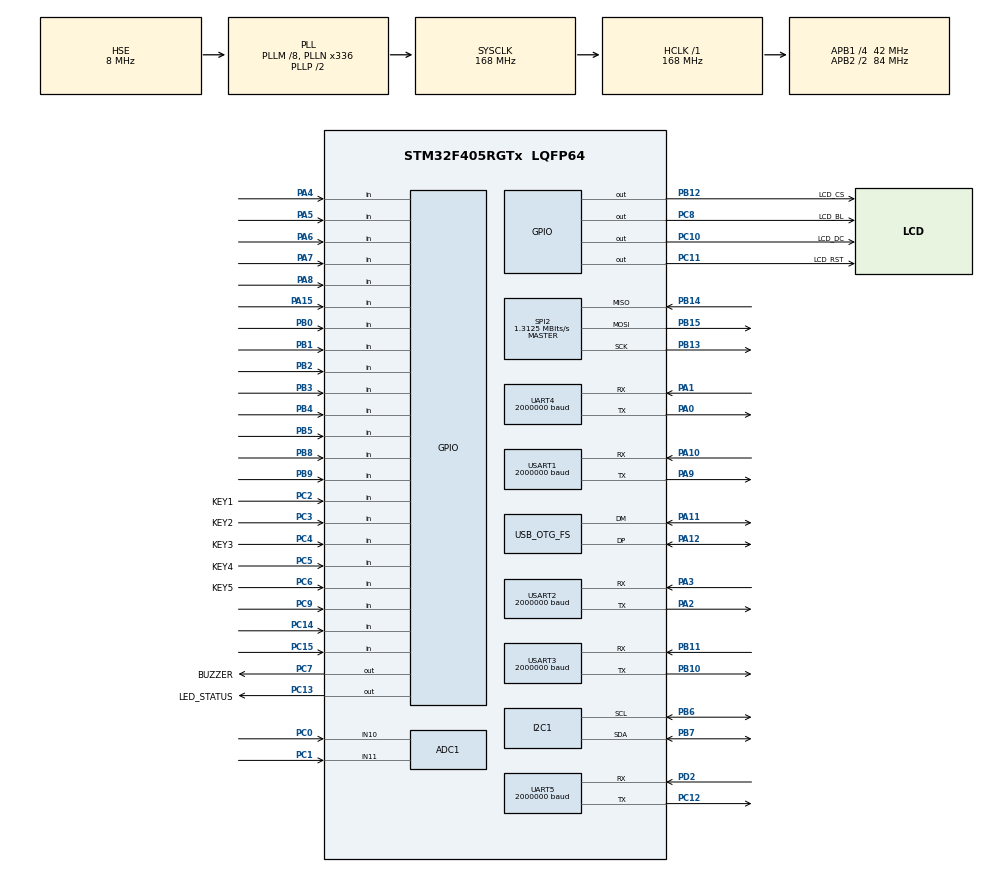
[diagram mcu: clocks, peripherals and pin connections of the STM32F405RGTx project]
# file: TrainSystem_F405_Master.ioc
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ADC1.Channel-3\#ChannelRegularConversion=ADC_CHANNEL_10
ADC1.Channel-6\#ChannelRegularConversion=ADC_CHANNEL_11
ADC1.InjNumberOfConversion=0
ADC1.NbrOfConversion=2
ADC1.NbrOfConversionFlag=1
ADC1.Rank-3\#ChannelRegularConversion=1
ADC1.Rank-6\#ChannelRegularConversion=2
ADC1.SamplingTime-3\#ChannelRegularConversion=ADC_SAMPLETIME_144CYCLES
ADC1.SamplingTime-6\#ChannelRegularConversion=ADC_SAMPLETIME_144CYCLES
ADC1.ScanConvMode=ENABLE
ADC1.master=1
Dma.ADC1.5.Direction=DMA_PERIPH_TO_MEMORY
Dma.ADC1.5.FIFOMode=DMA_FIFOMODE_DISABLE
Dma.ADC1.5.Instance=DMA2_Stream0
Dma.ADC1.5.MemDataAlignment=DMA_MDATAALIGN_HALFWORD
Dma.ADC1.5.MemInc=DMA_MINC_ENABLE
Dma.ADC1.5.Mode=DMA_CIRCULAR
Dma.ADC1.5.PeriphDataAlignment=DMA_PDATAALIGN_HALFWORD
Dma.ADC1.5.PeriphInc=DMA_PINC_DISABLE
Dma.ADC1.5.Priority=DMA_PRIORITY_LOW
Dma.Request0=UART5_RX
Dma.Request1=UART4_RX
Dma.Request2=USART1_RX
Dma.Request3=USART2_RX
Dma.Request4=USART3_RX
Dma.Request5=ADC1
Dma.UART4_RX.1.Direction=DMA_PERIPH_TO_MEMORY
Dma.UART4_RX.1.FIFOMode=DMA_FIFOMODE_DISABLE
Dma.UART4_RX.1.Instance=DMA1_Stream2
Dma.UART4_RX.1.MemDataAlignment=DMA_MDATAALIGN_BYTE
Dma.UART4_RX.1.MemInc=DMA_MINC_ENABLE
Dma.UART4_RX.1.Mode=DMA_CIRCULAR
Dma.UART4_RX.1.PeriphDataAlignment=DMA_PDATAALIGN_BYTE
Dma.UART4_RX.1.PeriphInc=DMA_PINC_DISABLE
Dma.UART4_RX.1.Priority=DMA_PRIORITY_HIGH
Dma.UART5_RX.0.Direction=DMA_PERIPH_TO_MEMORY
Dma.UART5_RX.0.FIFOMode=DMA_FIFOMODE_DISABLE
Dma.UART5_RX.0.Instance=DMA1_Stream0
Dma.UART5_RX.0.MemDataAlignment=DMA_MDATAALIGN_BYTE
Dma.UART5_RX.0.MemInc=DMA_MINC_ENABLE
Dma.UART5_RX.0.Mode=DMA_CIRCULAR
Dma.UART5_RX.0.PeriphDataAlignment=DMA_PDATAALIGN_BYTE
Dma.UART5_RX.0.PeriphInc=DMA_PINC_DISABLE
Dma.UART5_RX.0.Priority=DMA_PRIORITY_HIGH
Dma.USART1_RX.2.Direction=DMA_PERIPH_TO_MEMORY
Dma.USART1_RX.2.FIFOMode=DMA_FIFOMODE_DISABLE
Dma.USART1_RX.2.Instance=DMA2_Stream2
Dma.USART1_RX.2.MemDataAlignment=DMA_MDATAALIGN_BYTE
Dma.USART1_RX.2.MemInc=DMA_MINC_ENABLE
Dma.USART1_RX.2.Mode=DMA_CIRCULAR
Dma.USART1_RX.2.PeriphDataAlignment=DMA_PDATAALIGN_BYTE
Dma.USART1_RX.2.PeriphInc=DMA_PINC_DISABLE
Dma.USART1_RX.2.Priority=DMA_PRIORITY_HIGH
Dma.USART2_RX.3.Direction=DMA_PERIPH_TO_MEMORY
Dma.USART2_RX.3.FIFOMode=DMA_FIFOMODE_DISABLE
Dma.USART2_RX.3.Instance=DMA1_Stream5
Dma.USART2_RX.3.MemDataAlignment=DMA_MDATAALIGN_BYTE
Dma.USART2_RX.3.MemInc=DMA_MINC_ENABLE
Dma.USART2_RX.3.Mode=DMA_CIRCULAR
Dma.USART2_RX.3.PeriphDataAlignment=DMA_PDATAALIGN_BYTE
Dma.USART2_RX.3.PeriphInc=DMA_PINC_DISABLE
Dma.USART2_RX.3.Priority=DMA_PRIORITY_HIGH
Dma.USART3_RX.4.Direction=DMA_PERIPH_TO_MEMORY
Dma.USART3_RX.4.FIFOMode=DMA_FIFOMODE_DISABLE
Dma.USART3_RX.4.Instance=DMA1_Stream1
Dma.USART3_RX.4.MemDataAlignment=DMA_MDATAALIGN_BYTE
Dma.USART3_RX.4.MemInc=DMA_MINC_ENABLE
Dma.USART3_RX.4.Mode=DMA_CIRCULAR
Dma.USART3_RX.4.PeriphDataAlignment=DMA_PDATAALIGN_BYTE
Dma.USART3_RX.4.PeriphInc=DMA_PINC_DISABLE
Dma.USART3_RX.4.Priority=DMA_PRIORITY_HIGH
Mcu.Family=STM32F4
Mcu.Name=STM32F405RGTx
Mcu.Package=LQFP64
NVIC.DMA1_Stream0_IRQn=true\:0\:0\:false\:false\:true\:false\:true\:true
NVIC.DMA1_Stream1_IRQn=true\:0\:0\:false\:false\:true\:false\:true\:true
NVIC.DMA1_Stream2_IRQn=true\:0\:0\:false\:false\:true\:false\:true\:true
NVIC.DMA1_Stream5_IRQn=true\:0\:0\:false\:false\:true\:false\:true\:true
NVIC.DMA2_Stream0_IRQn=true\:0\:0\:false\:false\:true\:false\:true\:true
NVIC.DMA2_Stream2_IRQn=true\:0\:0\:false\:false\:true\:false\:true\:true
NVIC.OTG_FS_IRQn=true\:0\:0\:false\:false\:true\:false\:true\:true
NVIC.PriorityGroup=NVIC_PRIORITYGROUP_4
NVIC.UART4_IRQn=true\:0\:0\:false\:false\:true\:true\:true\:true
NVIC.UART5_IRQn=true\:0\:0\:false\:false\:true\:true\:true\:true
NVIC.USART1_IRQn=true\:0\:0\:false\:false\:true\:true\:true\:true
NVIC.USART2_IRQn=true\:0\:0\:false\:false\:true\:true\:true\:true
NVIC.USART3_IRQn=true\:0\:0\:false\:false\:true\:true\:true\:true
PA0-WKUP.Mode=Asynchronous
PA0-WKUP.Signal=UART4_TX
PA1.Mode=Asynchronous
PA1.Signal=UART4_RX
PA10.Mode=Asynchronous
PA10.Signal=USART1_RX
PA11.Mode=Device_Only
PA11.Signal=USB_OTG_FS_DM
PA12.Mode=Device_Only
PA12.Signal=USB_OTG_FS_DP
PA13.Mode=Serial_Wire
PA13.Signal=SYS_JTMS-SWDIO
PA14.Mode=Serial_Wire
PA14.Signal=SYS_JTCK-SWCLK
PA15.Signal=GPIO_Input
PA2.Mode=Asynchronous
PA2.Signal=USART2_TX
PA3.Mode=Asynchronous
PA3.Signal=USART2_RX
PA4.Signal=GPIO_Input
PA5.Signal=GPIO_Input
PA6.Signal=GPIO_Input
PA7.Signal=GPIO_Input
PA8.Signal=GPIO_Input
PA9.Mode=Asynchronous
PA9.Signal=USART1_TX
PB0.Signal=GPIO_Input
PB1.Signal=GPIO_Input
PB10.Mode=Asynchronous
PB10.Signal=USART3_TX
PB11.Mode=Asynchronous
PB11.Signal=USART3_RX
PB12.GPIO_Label=LCD_CS
PB12.PinState=GPIO_PIN_SET
PB12.Signal=GPIO_Output
PB13.Mode=Full_Duplex_Master
PB13.Signal=SPI2_SCK
PB14.Mode=Full_Duplex_Master
PB14.Signal=SPI2_MISO
PB15.Mode=Full_Duplex_Master
PB15.Signal=SPI2_MOSI
PB2.Signal=GPIO_Input
PB3.Signal=GPIO_Input
PB4.Signal=GPIO_Input
PB5.Signal=GPIO_Input
PB6.Mode=I2C
PB6.Signal=I2C1_SCL
PB7.Mode=I2C
PB7.Signal=I2C1_SDA
PB8.Signal=GPIO_Input
PB9.Signal=GPIO_Input
PC0.Signal=ADCx_IN10
PC1.Signal=ADCx_IN11
PC10.GPIO_Label=LCD_DC
PC10.Signal=GPIO_Output
PC11.GPIO_Label=LCD_RST
PC11.PinState=GPIO_PIN_SET
PC11.Signal=GPIO_Output
PC12.Mode=Asynchronous
PC12.Signal=UART5_TX
PC13-ANTI_TAMP.GPIO_Label=LED_STATUS
PC13-ANTI_TAMP.PinState=GPIO_PIN_SET
PC13-ANTI_TAMP.Signal=GPIO_Output
PC14-OSC32_IN.Signal=GPIO_Input
PC15-OSC32_OUT.Signal=GPIO_Input
PC2.GPIO_Label=KEY1
PC2.Signal=GPIO_Input
PC3.GPIO_Label=KEY2
PC3.Signal=GPIO_Input
PC4.GPIO_Label=KEY3
PC4.Signal=GPIO_Input
PC5.GPIO_Label=KEY4
PC5.Signal=GPIO_Input
PC6.GPIO_Label=KEY5
PC6.Signal=GPIO_Input
PC7.GPIO_Label=BUZZER
PC7.Signal=GPIO_Output
PC8.GPIO_Label=LCD_BL
PC8.Signal=GPIO_Output
PC9.Signal=GPIO_Input
PD2.Mode=Asynchronous
PD2.Signal=UART5_RX
PH0-OSC_IN.Mode=HSE-External-Oscillator
PH0-OSC_IN.Signal=RCC_OSC_IN
PH1-OSC_OUT.Mode=HSE-External-Oscillator
PH1-OSC_OUT.Signal=RCC_OSC_OUT
ProjectManager.HeapSize=0x200
ProjectManager.StackSize=0x400
ProjectManager.TargetToolchain=CMake
RCC.48MHZClocksFreq_Value=48000000
RCC.AHBFreq_Value=168000000
RCC.APB1CLKDivider=RCC_HCLK_DIV4
RCC.APB1Freq_Value=42000000
RCC.APB1TimFreq_Value=84000000
RCC.APB2CLKDivider=RCC_HCLK_DIV2
RCC.APB2Freq_Value=84000000
RCC.APB2TimFreq_Value=168000000
RCC.CortexFreq_Value=168000000
RCC.HCLKFreq_Value=168000000
RCC.HSE_VALUE=8000000
RCC.HSI_VALUE=16000000
RCC.LSE_VALUE=32768
RCC.PLLM=8
RCC.PLLN=336
RCC.PLLQ=7
RCC.SYSCLKFreq_VALUE=168000000
RCC.SYSCLKSource=RCC_SYSCLKSOURCE_PLLCLK
RCC.VCOOutputFreq_Value=336000000
SH.ADCx_IN10.0=ADC1_IN10,IN10
SH.ADCx_IN11.0=ADC1_IN11,IN11
SPI2.BaudRatePrescaler=SPI_BAUDRATEPRESCALER_32
SPI2.CalculateBaudRate=1.3125 MBits/s
SPI2.Direction=SPI_DIRECTION_2LINES
SPI2.Mode=SPI_MODE_MASTER
SPI2.VirtualType=VM_MASTER
UART4.BaudRate=2000000
UART4.VirtualMode=Asynchronous
UART5.BaudRate=2000000
UART5.VirtualMode=Asynchronous
USART1.BaudRate=2000000
USART1.VirtualMode=VM_ASYNC
USART2.BaudRate=2000000
USART2.VirtualMode=VM_ASYNC
USART3.BaudRate=2000000
USART3.VirtualMode=VM_ASYNC
USB_DEVICE.CLASS_NAME_FS=CDC
USB_DEVICE.VirtualMode-CDC_FS=Cdc
USB_DEVICE.VirtualModeFS=Cdc_FS
USB_OTG_FS.VirtualMode=Device_Only
VP_USB_DEVICE_VS_USB_DEVICE_CDC_FS.Mode=CDC_FS
board=custom

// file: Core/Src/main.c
/* USER CODE BEGIN Header */
/**
  ******************************************************************************
  * @file           : main.c
  * @brief          : Main program body
  ******************************************************************************
  * @attention
  *
  * Copyright (c) 2026 STMicroelectronics.
  * All rights reserved.
  *
  * This software is licensed under terms that can be found in the LICENSE file
  * in the root directory of this software component.
  * If no LICENSE file comes with this software, it is provided AS-IS.
  *
  ******************************************************************************
  */
/* USER CODE END Header */
#include "main.h"
#include "adc.h"
#include "dma.h"
#include "i2c.h"
#include "spi.h"
#include "usart.h"
#include "usb_device.h"
#include "gpio.h"

/* USER CODE BEGIN Includes */
#include "app_main.h"

/* USER CODE END Includes */

void SystemClock_Config(void);

int main(void)
{

  /* MCU Configuration--------------------------------------------------------*/

  /* Reset of all peripherals, Initializes the Flash interface and the Systick. */
  HAL_Init();

  /* Configure the system clock */
  SystemClock_Config();

  /* Initialize all configured peripherals */
  MX_GPIO_Init();
  MX_DMA_Init();
  MX_UART4_Init();
  MX_UART5_Init();
  MX_USART1_UART_Init();
  MX_USART2_UART_Init();
  MX_USART3_UART_Init();
  MX_USB_DEVICE_Init();
  MX_ADC1_Init();
  MX_I2C1_Init();
  MX_SPI2_Init();
  /* USER CODE BEGIN 2 */
  app_main_init();

  /* USER CODE END 2 */

  /* Infinite loop */
  while (1)
  {

    /* USER CODE BEGIN 3 */
    app_main_loop();
  }
  /* USER CODE END 3 */
}

void SystemClock_Config(void)
{
  RCC_OscInitTypeDef RCC_OscInitStruct = {0};
  RCC_ClkInitTypeDef RCC_ClkInitStruct = {0};

  /** Configure the main internal regulator output voltage
  */
  __HAL_RCC_PWR_CLK_ENABLE();
  __HAL_PWR_VOLTAGESCALING_CONFIG(PWR_REGULATOR_VOLTAGE_SCALE1);

  /** Initializes the RCC Oscillators according to the specified parameters
  * in the RCC_OscInitTypeDef structure.
  */
  RCC_OscInitStruct.OscillatorType = RCC_OSCILLATORTYPE_HSE;
  RCC_OscInitStruct.HSEState = RCC_HSE_ON;
  RCC_OscInitStruct.PLL.PLLState = RCC_PLL_ON;
  RCC_OscInitStruct.PLL.PLLSource = RCC_PLLSOURCE_HSE;
  RCC_OscInitStruct.PLL.PLLM = 8;
  RCC_OscInitStruct.PLL.PLLN = 336;
  RCC_OscInitStruct.PLL.PLLP = RCC_PLLP_DIV2;
  RCC_OscInitStruct.PLL.PLLQ = 7;
  if (HAL_RCC_OscConfig(&RCC_OscInitStruct) != HAL_OK)
  {
    Error_Handler();
  }

  /** Initializes the CPU, AHB and APB buses clocks
  */
  RCC_ClkInitStruct.ClockType = RCC_CLOCKTYPE_HCLK|RCC_CLOCKTYPE_SYSCLK
                              |RCC_CLOCKTYPE_PCLK1|RCC_CLOCKTYPE_PCLK2;
  RCC_ClkInitStruct.SYSCLKSource = RCC_SYSCLKSOURCE_PLLCLK;
  RCC_ClkInitStruct.AHBCLKDivider = RCC_SYSCLK_DIV1;
  RCC_ClkInitStruct.APB1CLKDivider = RCC_HCLK_DIV4;
  RCC_ClkInitStruct.APB2CLKDivider = RCC_HCLK_DIV2;

  if (HAL_RCC_ClockConfig(&RCC_ClkInitStruct, FLASH_LATENCY_5) != HAL_OK)
  {
    Error_Handler();
  }
}

void Error_Handler(void)
{
  /* USER CODE BEGIN Error_Handler_Debug */
  __disable_irq();
  while (1)
  {
    HAL_GPIO_TogglePin(LED_STATUS_GPIO_Port, LED_STATUS_Pin);
    for (volatile uint32_t i = 0; i < 800000U; i++) {
    }
  }
  /* USER CODE END Error_Handler_Debug */
}
